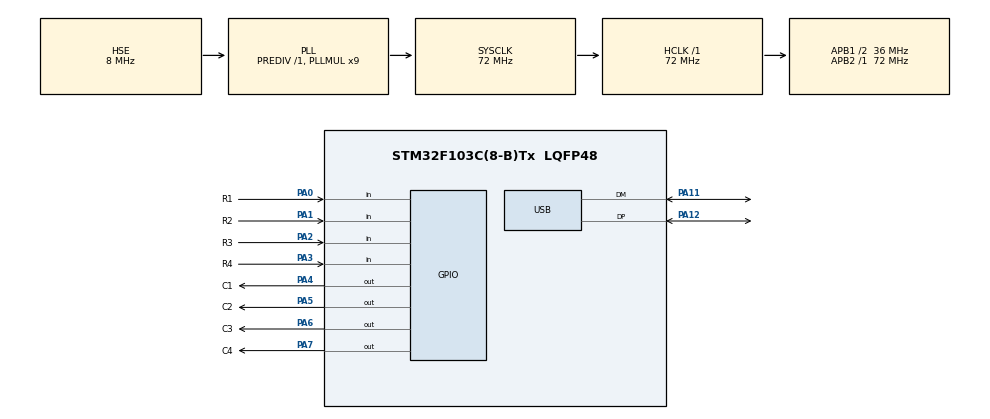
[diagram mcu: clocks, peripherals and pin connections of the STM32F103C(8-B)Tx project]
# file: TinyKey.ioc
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Mcu.Family=STM32F1
Mcu.Name=STM32F103C(8-B)Tx
Mcu.Package=LQFP48
NVIC.PriorityGroup=NVIC_PRIORITYGROUP_4
NVIC.USB_LP_CAN1_RX0_IRQn=true\:0\:0\:false\:false\:true\:false\:true\:true
PA0-WKUP.GPIO_Label=R1
PA0-WKUP.GPIO_PuPd=GPIO_PULLDOWN
PA0-WKUP.Signal=GPIO_Input
PA1.GPIO_Label=R2
PA1.GPIO_PuPd=GPIO_PULLDOWN
PA1.Signal=GPIO_Input
PA11.Mode=Device
PA11.Signal=USB_DM
PA12.Mode=Device
PA12.Signal=USB_DP
PA13.Mode=Serial_Wire
PA13.Signal=SYS_JTMS-SWDIO
PA14.Mode=Serial_Wire
PA14.Signal=SYS_JTCK-SWCLK
PA2.GPIO_Label=R3
PA2.GPIO_PuPd=GPIO_PULLDOWN
PA2.Signal=GPIO_Input
PA3.GPIO_Label=R4
PA3.GPIO_PuPd=GPIO_PULLDOWN
PA3.Signal=GPIO_Input
PA4.GPIO_Label=C1
PA4.GPIO_PuPd=GPIO_NOPULL
PA4.GPIO_Speed=GPIO_SPEED_FREQ_HIGH
PA4.PinState=GPIO_PIN_RESET
PA4.Signal=GPIO_Output
PA5.GPIO_Label=C2
PA5.GPIO_PuPd=GPIO_NOPULL
PA5.GPIO_Speed=GPIO_SPEED_FREQ_HIGH
PA5.PinState=GPIO_PIN_RESET
PA5.Signal=GPIO_Output
PA6.GPIO_Label=C3
PA6.GPIO_PuPd=GPIO_NOPULL
PA6.GPIO_Speed=GPIO_SPEED_FREQ_HIGH
PA6.PinState=GPIO_PIN_RESET
PA6.Signal=GPIO_Output
PA7.GPIO_Label=C4
PA7.GPIO_ModeDefaultOutputPP=GPIO_MODE_OUTPUT_PP
PA7.GPIO_PuPd=GPIO_NOPULL
PA7.GPIO_Speed=GPIO_SPEED_FREQ_HIGH
PA7.PinState=GPIO_PIN_RESET
PA7.Signal=GPIO_Output
PC14-OSC32_IN.Mode=LSE-External-Oscillator
PC14-OSC32_IN.Signal=RCC_OSC32_IN
PC15-OSC32_OUT.Mode=LSE-External-Oscillator
PC15-OSC32_OUT.Signal=RCC_OSC32_OUT
PD0-OSC_IN.Mode=HSE-External-Oscillator
PD0-OSC_IN.Signal=RCC_OSC_IN
PD1-OSC_OUT.Mode=HSE-External-Oscillator
PD1-OSC_OUT.Signal=RCC_OSC_OUT
ProjectManager.HeapSize=0x200
ProjectManager.StackSize=0x400
ProjectManager.TargetToolchain=MDK-ARM V5.32
RCC.AHBFreq_Value=72000000
RCC.APB1CLKDivider=RCC_HCLK_DIV2
RCC.APB1Freq_Value=36000000
RCC.APB1TimFreq_Value=72000000
RCC.APB2Freq_Value=72000000
RCC.APB2TimFreq_Value=72000000
RCC.HCLKFreq_Value=72000000
RCC.PLLMUL=RCC_PLL_MUL9
RCC.PLLSourceVirtual=RCC_PLLSOURCE_HSE
RCC.SYSCLKFreq_VALUE=72000000
RCC.SYSCLKSource=RCC_SYSCLKSOURCE_PLLCLK
RCC.USBFreq_Value=48000000
RCC.USBPrescaler=RCC_USBCLKSOURCE_PLL_DIV1_5
USB_DEVICE.CLASS_NAME_FS=HID
USB_DEVICE.VirtualMode=Hid
USB_DEVICE.VirtualModeFS=Hid_FS
VP_USB_DEVICE_VS_USB_DEVICE_HID_FS.Mode=HID_FS
board=custom

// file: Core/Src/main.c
/* USER CODE BEGIN Header */
/**
  ******************************************************************************
  * @file           : main.c
  * @brief          : Main program body
  ******************************************************************************
  * @attention
  *
  * Copyright (c) 2026 STMicroelectronics.
  * All rights reserved.
  *
  * This software is licensed under terms that can be found in the LICENSE file
  * in the root directory of this software component.
  * If no LICENSE file comes with this software, it is provided AS-IS.
  *
  ******************************************************************************
  */
/* USER CODE END Header */
#include "main.h"
#include "usb_device.h"
#include "gpio.h"

/* USER CODE BEGIN Includes */
#include "keyboard.h"
/* USER CODE END Includes */

void SystemClock_Config(void);

int main(void)
{

  /* MCU Configuration--------------------------------------------------------*/

  /* Reset of all peripherals, Initializes the Flash interface and the Systick. */
  HAL_Init();

  /* Configure the system clock */
  SystemClock_Config();

  /* Initialize all configured peripherals */
  MX_GPIO_Init();
  MX_USB_DEVICE_Init();
  /* USER CODE BEGIN 2 */
  /* 初始化 4x4 矩阵键盘：扫描 + 消抖 + USB HID 上报 */
  KB_Init();
  /* USER CODE END 2 */

  /* Infinite loop */
  while (1)
  {

    /* USER CODE BEGIN 3 */
    /* 内部自行节流到 1ms 一轮扫描，空闲时立即返回，不影响 USB 中断响应 */
    KB_Task();
  }
  /* USER CODE END 3 */
}

void SystemClock_Config(void)
{
  RCC_OscInitTypeDef RCC_OscInitStruct = {0};
  RCC_ClkInitTypeDef RCC_ClkInitStruct = {0};
  RCC_PeriphCLKInitTypeDef PeriphClkInit = {0};

  /** Initializes the RCC Oscillators according to the specified parameters
  * in the RCC_OscInitTypeDef structure.
  */
  RCC_OscInitStruct.OscillatorType = RCC_OSCILLATORTYPE_HSE;
  RCC_OscInitStruct.HSEState = RCC_HSE_ON;
  RCC_OscInitStruct.HSEPredivValue = RCC_HSE_PREDIV_DIV1;
  RCC_OscInitStruct.HSIState = RCC_HSI_ON;
  RCC_OscInitStruct.PLL.PLLState = RCC_PLL_ON;
  RCC_OscInitStruct.PLL.PLLSource = RCC_PLLSOURCE_HSE;
  RCC_OscInitStruct.PLL.PLLMUL = RCC_PLL_MUL9;
  if (HAL_RCC_OscConfig(&RCC_OscInitStruct) != HAL_OK)
  {
    Error_Handler();
  }

  /** Initializes the CPU, AHB and APB buses clocks
  */
  RCC_ClkInitStruct.ClockType = RCC_CLOCKTYPE_HCLK|RCC_CLOCKTYPE_SYSCLK
                              |RCC_CLOCKTYPE_PCLK1|RCC_CLOCKTYPE_PCLK2;
  RCC_ClkInitStruct.SYSCLKSource = RCC_SYSCLKSOURCE_PLLCLK;
  RCC_ClkInitStruct.AHBCLKDivider = RCC_SYSCLK_DIV1;
  RCC_ClkInitStruct.APB1CLKDivider = RCC_HCLK_DIV2;
  RCC_ClkInitStruct.APB2CLKDivider = RCC_HCLK_DIV1;

  if (HAL_RCC_ClockConfig(&RCC_ClkInitStruct, FLASH_LATENCY_2) != HAL_OK)
  {
    Error_Handler();
  }
  PeriphClkInit.PeriphClockSelection = RCC_PERIPHCLK_USB;
  PeriphClkInit.UsbClockSelection = RCC_USBCLKSOURCE_PLL_DIV1_5;
  if (HAL_RCCEx_PeriphCLKConfig(&PeriphClkInit) != HAL_OK)
  {
    Error_Handler();
  }
}

void Error_Handler(void)
{
  __disable_irq();
  while (1)
  {
  }
}
